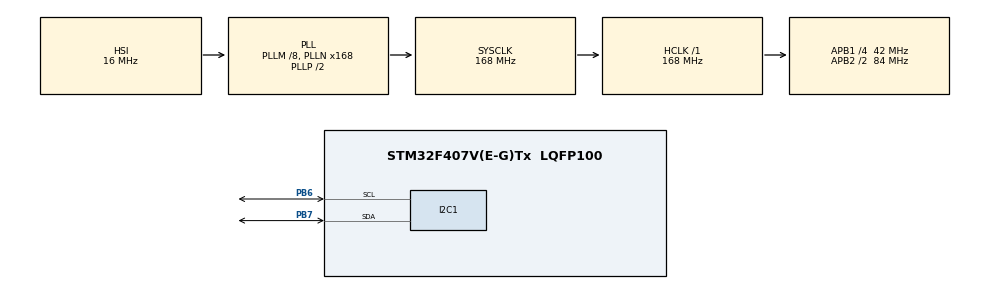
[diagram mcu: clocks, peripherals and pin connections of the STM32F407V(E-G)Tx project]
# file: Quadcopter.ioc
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I2C1.I2C_Mode=I2C_Fast
Mcu.Family=STM32F4
Mcu.Name=STM32F407V(E-G)Tx
Mcu.Package=LQFP100
NVIC.PriorityGroup=NVIC_PRIORITYGROUP_4
NVIC.TIM2_IRQn=true\:0\:0\:false\:false\:true\:true\:true
PA13.Mode=Serial_Wire
PA13.Signal=SYS_JTMS-SWDIO
PA14.Mode=Serial_Wire
PA14.Signal=SYS_JTCK-SWCLK
PB6.Mode=I2C
PB6.Signal=I2C1_SCL
PB7.Mode=I2C
PB7.Signal=I2C1_SDA
ProjectManager.HeapSize=0x200
ProjectManager.StackSize=0x400
ProjectManager.TargetToolchain=STM32CubeIDE
RCC.48MHZClocksFreq_Value=84000000
RCC.AHBFreq_Value=168000000
RCC.APB1CLKDivider=RCC_HCLK_DIV4
RCC.APB1Freq_Value=42000000
RCC.APB1TimFreq_Value=84000000
RCC.APB2CLKDivider=RCC_HCLK_DIV2
RCC.APB2Freq_Value=84000000
RCC.APB2TimFreq_Value=168000000
RCC.CortexFreq_Value=168000000
RCC.HCLKFreq_Value=168000000
RCC.HSE_VALUE=25000000
RCC.HSI_VALUE=16000000
RCC.LSE_VALUE=32768
RCC.PLLM=8
RCC.PLLN=168
RCC.SYSCLKFreq_VALUE=168000000
RCC.SYSCLKSource=RCC_SYSCLKSOURCE_PLLCLK
RCC.VCOOutputFreq_Value=336000000
TIM2.AutoReloadPreload=TIM_AUTORELOAD_PRELOAD_ENABLE
TIM2.Period=168
TIM2.Prescaler=1000
VP_TIM2_VS_ClockSourceINT.Mode=Internal
board=custom

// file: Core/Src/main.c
/* USER CODE BEGIN Header */
/**
  ******************************************************************************
  * @file           : main.c
  * @brief          : Main program body
  ******************************************************************************
  * @attention
  *
  * <h2><center>&copy; Copyright (c) 2022 STMicroelectronics.
  * All rights reserved.</center></h2>
  *
  * This software component is licensed by ST under BSD 3-Clause license,
  * the "License"; You may not use this file except in compliance with the
  * License. You may obtain a copy of the License at:
  *                        opensource.org/licenses/BSD-3-Clause
  *
  ******************************************************************************
  */
/* USER CODE END Header */
#include "main.h"

/* USER CODE BEGIN Includes */
#include <stdio.h>
#include <stdlib.h>
#include <string.h>
#include <math.h>
#include <stdbool.h>
#include "PID.h"
#include "Gain_Scheduling.h"
#include "simpMat.h"
/* USER CODE END Includes */

/* USER CODE BEGIN PD */
#define MPU6050_ADDR 		0x68<<1
#define PWR_MGMT_1_REG 		0x6B
#define SMPLRT_DIV_REG 		0x19
#define GYRO_CNFG_REG 		0x1B
#define ACC_CNFG_REG 		0x1C
#define b 					0.000017911
#define d					0.0000006888
#define l					0.225
/* USER CODE END PD */

I2C_HandleTypeDef hi2c1;

TIM_HandleTypeDef htim2;

/* USER CODE BEGIN PV */
uint8_t 	data;
uint8_t 	buffer[2], tuffer[6], cuffer[6]; // raw gyro and acc data
int16_t 	gyro_raw[3], acc_raw[3];
float 		gyro_cal[3];
int16_t 	acc_total_vector;
float 		angle_pitch_gyro, angle_roll_gyro;
float 		angle_pitch_acc, angle_roll_acc;
float 		angle_pitch, angle_roll;
int16_t 	raw_temp;
float 		U1_out;
float 		U2_out;
float 		U3_out;
float 		U4_out;

simpMat motorMatrix;
const float motorMatrixValues[16] =
		{1/(4*b),  1/(4*b*l),  1/(4*b*l), -1/(4*d),
		1/(4*b), -1/(4*b*l),  1/(4*b*l),  1/(4*d),
		1/(4*b), -1/(4*b*l), -1/(4*b*l), -1/(4*d),
		1/(4*b),  1/(4*b*l), -1/(4*b*l),  1/(4*d)};

/* USER CODE END PV */

void SystemClock_Config(void);
static void MX_GPIO_Init(void);
static void MX_I2C1_Init(void);
static void MX_TIM2_Init(void);

int main(void)
{

  /* MCU Configuration--------------------------------------------------------*/

  /* Reset of all peripherals, Initializes the Flash interface and the Systick. */
  HAL_Init();

  /* USER CODE BEGIN Init */
  simpMat_Init(&motorMatrix, 4, 4, motorMatrixValues);
  /* USER CODE END Init */

  /* Configure the system clock */
  SystemClock_Config();

  /* Initialize all configured peripherals */
  MX_GPIO_Init();
  MX_I2C1_Init();
  MX_TIM2_Init();

  /* Infinite loop */
  while (1)
  {

  }
}

void SystemClock_Config(void)
{
  RCC_OscInitTypeDef RCC_OscInitStruct = {0};
  RCC_ClkInitTypeDef RCC_ClkInitStruct = {0};

  /** Configure the main internal regulator output voltage
  */
  __HAL_RCC_PWR_CLK_ENABLE();
  __HAL_PWR_VOLTAGESCALING_CONFIG(PWR_REGULATOR_VOLTAGE_SCALE1);
  /** Initializes the RCC Oscillators according to the specified parameters
  * in the RCC_OscInitTypeDef structure.
  */
  RCC_OscInitStruct.OscillatorType = RCC_OSCILLATORTYPE_HSI;
  RCC_OscInitStruct.HSIState = RCC_HSI_ON;
  RCC_OscInitStruct.HSICalibrationValue = RCC_HSICALIBRATION_DEFAULT;
  RCC_OscInitStruct.PLL.PLLState = RCC_PLL_ON;
  RCC_OscInitStruct.PLL.PLLSource = RCC_PLLSOURCE_HSI;
  RCC_OscInitStruct.PLL.PLLM = 8;
  RCC_OscInitStruct.PLL.PLLN = 168;
  RCC_OscInitStruct.PLL.PLLP = RCC_PLLP_DIV2;
  RCC_OscInitStruct.PLL.PLLQ = 4;
  if (HAL_RCC_OscConfig(&RCC_OscInitStruct) != HAL_OK)
  {
    Error_Handler();
  }
  /** Initializes the CPU, AHB and APB buses clocks
  */
  RCC_ClkInitStruct.ClockType = RCC_CLOCKTYPE_HCLK|RCC_CLOCKTYPE_SYSCLK
                              |RCC_CLOCKTYPE_PCLK1|RCC_CLOCKTYPE_PCLK2;
  RCC_ClkInitStruct.SYSCLKSource = RCC_SYSCLKSOURCE_PLLCLK;
  RCC_ClkInitStruct.AHBCLKDivider = RCC_SYSCLK_DIV1;
  RCC_ClkInitStruct.APB1CLKDivider = RCC_HCLK_DIV4;
  RCC_ClkInitStruct.APB2CLKDivider = RCC_HCLK_DIV2;

  if (HAL_RCC_ClockConfig(&RCC_ClkInitStruct, FLASH_LATENCY_5) != HAL_OK)
  {
    Error_Handler();
  }
}

static void MX_I2C1_Init(void)
{

  hi2c1.Instance = I2C1;
  hi2c1.Init.ClockSpeed = 400000;
  hi2c1.Init.DutyCycle = I2C_DUTYCYCLE_2;
  hi2c1.Init.OwnAddress1 = 0;
  hi2c1.Init.AddressingMode = I2C_ADDRESSINGMODE_7BIT;
  hi2c1.Init.DualAddressMode = I2C_DUALADDRESS_DISABLE;
  hi2c1.Init.OwnAddress2 = 0;
  hi2c1.Init.GeneralCallMode = I2C_GENERALCALL_DISABLE;
  hi2c1.Init.NoStretchMode = I2C_NOSTRETCH_DISABLE;
  if (HAL_I2C_Init(&hi2c1) != HAL_OK)
  {
    Error_Handler();
  }

}

static void MX_TIM2_Init(void)
{

  TIM_ClockConfigTypeDef sClockSourceConfig = {0};
  TIM_MasterConfigTypeDef sMasterConfig = {0};

  htim2.Instance = TIM2;
  htim2.Init.Prescaler = 1000;
  htim2.Init.CounterMode = TIM_COUNTERMODE_UP;
  htim2.Init.Period = 168;
  htim2.Init.ClockDivision = TIM_CLOCKDIVISION_DIV1;
  htim2.Init.AutoReloadPreload = TIM_AUTORELOAD_PRELOAD_ENABLE;
  if (HAL_TIM_Base_Init(&htim2) != HAL_OK)
  {
    Error_Handler();
  }
  sClockSourceConfig.ClockSource = TIM_CLOCKSOURCE_INTERNAL;
  if (HAL_TIM_ConfigClockSource(&htim2, &sClockSourceConfig) != HAL_OK)
  {
    Error_Handler();
  }
  sMasterConfig.MasterOutputTrigger = TIM_TRGO_RESET;
  sMasterConfig.MasterSlaveMode = TIM_MASTERSLAVEMODE_DISABLE;
  if (HAL_TIMEx_MasterConfigSynchronization(&htim2, &sMasterConfig) != HAL_OK)
  {
    Error_Handler();
  }

}

static void MX_GPIO_Init(void)
{

  /* GPIO Ports Clock Enable */
  __HAL_RCC_GPIOA_CLK_ENABLE();
  __HAL_RCC_GPIOB_CLK_ENABLE();

}

/* USER CODE BEGIN 4 */
void HAL_TIM_PeriodElapsedCallback(TIM_HandleTypeDef* htim)
{

}

/* USER CODE END 4 */

void Error_Handler(void)
{
  __disable_irq();
  while (1)
  {
  }
}

/************************ (C) COPYRIGHT STMicroelectronics *****END OF FILE****/
